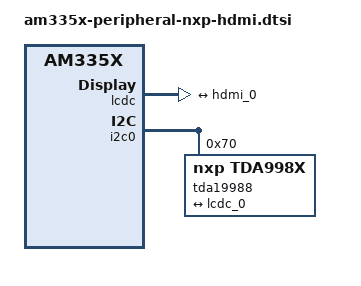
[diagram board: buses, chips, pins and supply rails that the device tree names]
// SPDX-License-Identifier: GPL-2.0-only
/*
 * Copyright (C) 2012 Texas Instruments Incorporated - https://www.ti.com/
 */

&lcdc {
	status = "okay";
	port {
		lcdc_0: endpoint@0 {
			remote-endpoint = <&hdmi_0>;
		};
	};
};

&i2c0 {
	tda19988 {
		compatible = "nxp,tda998x";
		reg = <0x70>;

		port {
			hdmi_0: endpoint@0 {
				remote-endpoint = <&lcdc_0>;
			};
		};
	};
};
